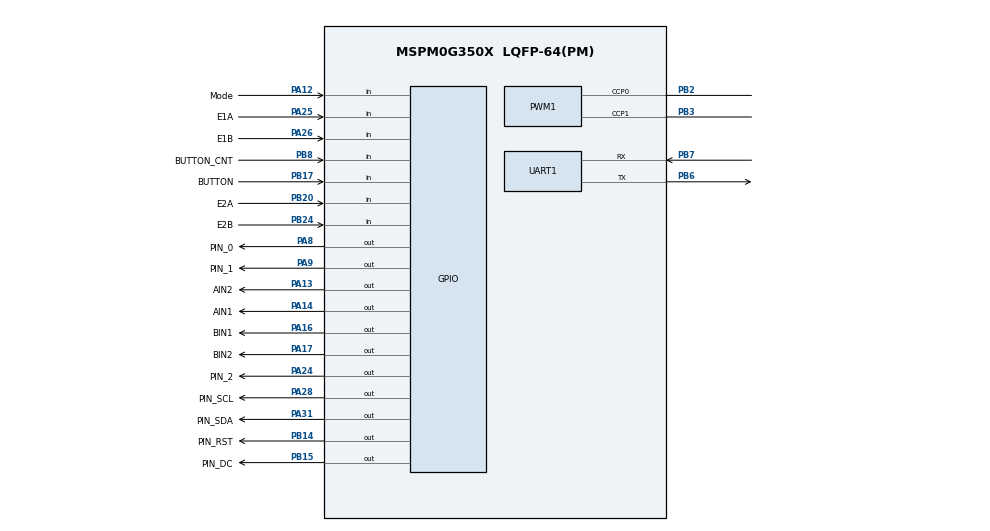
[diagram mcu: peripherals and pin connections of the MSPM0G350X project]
/**
 *
 * @cliArgs --device "MSPM0G350X" --part "Default" --package "LQFP-64(PM)" --product "mspm0_sdk@2.10.00.04"
 * @versions {"tool":"1.28.0+4696"}
 */

/**
 * Import the modules used in this configuration.
 */
const ADC12   = scripting.addModule("/ti/driverlib/ADC12", {}, false);
const ADC121  = ADC12.addInstance();
const DMA     = scripting.addModule("/ti/driverlib/DMA");
const GPIO    = scripting.addModule("/ti/driverlib/GPIO", {}, false);
const GPIO1   = GPIO.addInstance();
const GPIO2   = GPIO.addInstance();
const GPIO3   = GPIO.addInstance();
const GPIO4   = GPIO.addInstance();
const GPIO5   = GPIO.addInstance();
const GPIO6   = GPIO.addInstance();
const GPIO7   = GPIO.addInstance();
const GPIO8   = GPIO.addInstance();
const GPIO9   = GPIO.addInstance();
const GPIO10  = GPIO.addInstance();
const PWM     = scripting.addModule("/ti/driverlib/PWM", {}, false);
const PWM1    = PWM.addInstance();
const SYSCTL  = scripting.addModule("/ti/driverlib/SYSCTL");
const SYSTICK = scripting.addModule("/ti/driverlib/SYSTICK");
const TIMER   = scripting.addModule("/ti/driverlib/TIMER", {}, false);
const TIMER1  = TIMER.addInstance();
const UART    = scripting.addModule("/ti/driverlib/UART", {}, false);
const UART1   = UART.addInstance();

/**
 * Write custom configuration values to the imported modules.
 */
const divider7       = system.clockTree["PLL_PDIV"];
divider7.divideValue = 2;

const divider9       = system.clockTree["UDIV"];
divider9.divideValue = 2;

const multiplier2         = system.clockTree["PLL_QDIV"];
multiplier2.multiplyValue = 5;

const mux8       = system.clockTree["HSCLKMUX"];
mux8.inputSelect = "HSCLKMUX_SYSPLL2X";

ADC121.$name                      = "ADC12_0";
ADC121.sampleTime0                = "2 us";
ADC121.sampClkDiv                 = "DL_ADC12_CLOCK_DIVIDE_8";
ADC121.enabledInterrupts          = ["DL_ADC12_INTERRUPT_MEM0_RESULT_LOADED"];
ADC121.adcMem0_name               = "ADC_CH0";
ADC121.repeatMode                 = true;
ADC121.peripheral.$assign         = "ADC0";
ADC121.peripheral.adcPin0.$assign = "PA27";
ADC121.adcPin0Config.$name        = "ti_driverlib_gpio_GPIOPinGeneric2";

const Board = scripting.addModule("/ti/driverlib/Board", {}, false);

GPIO1.$name                         = "Gray_Address";
GPIO1.associatedPins.create(3);
GPIO1.associatedPins[0].$name       = "PIN_0";
GPIO1.associatedPins[0].pin.$assign = "PA8";
GPIO1.associatedPins[1].$name       = "PIN_1";
GPIO1.associatedPins[1].pin.$assign = "PA9";
GPIO1.associatedPins[2].$name       = "PIN_2";
GPIO1.associatedPins[2].pin.$assign = "PA24";

GPIO2.$name                         = "AIN";
GPIO2.port                          = "PORTA";
GPIO2.associatedPins.create(2);
GPIO2.associatedPins[0].$name       = "AIN1";
GPIO2.associatedPins[0].pin.$assign = "PA14";
GPIO2.associatedPins[1].$name       = "AIN2";
GPIO2.associatedPins[1].pin.$assign = "PA13";

GPIO3.$name                         = "BIN";
GPIO3.port                          = "PORTA";
GPIO3.associatedPins.create(2);
GPIO3.associatedPins[0].$name       = "BIN1";
GPIO3.associatedPins[0].pin.$assign = "PA16";
GPIO3.associatedPins[1].$name       = "BIN2";
GPIO3.associatedPins[1].pin.$assign = "PA17";

GPIO4.$name                               = "ENCODERA";
GPIO4.associatedPins.create(3);
GPIO4.associatedPins[0].$name             = "E1A";
GPIO4.associatedPins[0].direction         = "INPUT";
GPIO4.associatedPins[0].interruptEn       = true;
GPIO4.associatedPins[0].polarity          = "RISE";
GPIO4.associatedPins[0].interruptPriority = "0";
GPIO4.associatedPins[0].pin.$assign       = "PA25";
GPIO4.associatedPins[1].$name             = "E1B";
GPIO4.associatedPins[1].direction         = "INPUT";
GPIO4.associatedPins[1].interruptEn       = true;
GPIO4.associatedPins[1].polarity          = "RISE";
GPIO4.associatedPins[1].pin.$assign       = "PA26";
GPIO4.associatedPins[2].$name             = "Mode";
GPIO4.associatedPins[2].direction         = "INPUT";
GPIO4.associatedPins[2].interruptEn       = true;
GPIO4.associatedPins[2].polarity          = "FALL";
GPIO4.associatedPins[2].internalResistor  = "PULL_UP";
GPIO4.associatedPins[2].pin.$assign       = "PA12";

GPIO5.$name                               = "ENCODERB";
GPIO5.associatedPins.create(3);
GPIO5.associatedPins[0].$name             = "E2A";
GPIO5.associatedPins[0].direction         = "INPUT";
GPIO5.associatedPins[0].interruptEn       = true;
GPIO5.associatedPins[0].polarity          = "RISE";
GPIO5.associatedPins[0].interruptPriority = "0";
GPIO5.associatedPins[0].pin.$assign       = "PB20";
GPIO5.associatedPins[1].$name             = "E2B";
GPIO5.associatedPins[1].direction         = "INPUT";
GPIO5.associatedPins[1].polarity          = "RISE_FALL";
GPIO5.associatedPins[1].interruptEn       = true;
GPIO5.associatedPins[1].pin.$assign       = "PB24";
GPIO5.associatedPins[2].$name             = "BUTTON";
GPIO5.associatedPins[2].direction         = "INPUT";
GPIO5.associatedPins[2].internalResistor  = "PULL_UP";
GPIO5.associatedPins[2].interruptEn       = true;
GPIO5.associatedPins[2].polarity          = "FALL";
GPIO5.associatedPins[2].pin.$assign       = "PB17";

GPIO6.$name                         = "OLED_RST";
GPIO6.associatedPins[0].$name       = "PIN_RST";
GPIO6.associatedPins[0].pin.$assign = "PB14";

GPIO7.$name                         = "OLED_DC";
GPIO7.associatedPins[0].$name       = "PIN_DC";
GPIO7.associatedPins[0].pin.$assign = "PB15";

GPIO8.$name                         = "OLED_SCL";
GPIO8.associatedPins[0].$name       = "PIN_SCL";
GPIO8.associatedPins[0].pin.$assign = "PA28";

GPIO9.$name                         = "OLED_SDA";
GPIO9.associatedPins[0].$name       = "PIN_SDA";
GPIO9.associatedPins[0].pin.$assign = "PA31";

GPIO10.$name                              = "COUNT_BTN";
GPIO10.associatedPins[0].$name            = "BUTTON_CNT";
GPIO10.associatedPins[0].direction        = "INPUT";
GPIO10.associatedPins[0].internalResistor = "PULL_UP";
GPIO10.associatedPins[0].polarity         = "FALL";
GPIO10.associatedPins[0].pin.$assign      = "PB8";

PWM1.$name                      = "PWM_0";
PWM1.pwmMode                    = "EDGE_ALIGN_UP";
PWM1.timerStartTimer            = true;
PWM1.timerCount                 = 8000;
PWM1.peripheral.$assign         = "TIMA1";
PWM1.peripheral.ccp0Pin.$assign = "PB2";
PWM1.peripheral.ccp1Pin.$assign = "PB3";
PWM1.PWM_CHANNEL_0.$name        = "ti_driverlib_pwm_PWMTimerCC0";
PWM1.PWM_CHANNEL_1.$name        = "ti_driverlib_pwm_PWMTimerCC1";
PWM1.ccp0PinConfig.$name        = "ti_driverlib_gpio_GPIOPinGeneric3";
PWM1.ccp1PinConfig.$name        = "ti_driverlib_gpio_GPIOPinGeneric4";

SYSCTL.forceDefaultClkConfig = true;
SYSCTL.clockTreeEn           = true;

SYSTICK.periodEnable    = true;
SYSTICK.period          = 32000;
SYSTICK.interruptEnable = true;
SYSTICK.systickEnable   = true;

TIMER1.$name             = "TIMER_0";
TIMER1.timerPeriod       = "10 ms";
TIMER1.timerClkPrescale  = 32;
TIMER1.timerMode         = "PERIODIC_UP";
TIMER1.interrupts        = ["ZERO"];
TIMER1.interruptPriority = "1";

UART1.enabledInterrupts                    = ["RX"];
UART1.$name                                = "UART_JY61P";
UART1.interruptPriority                    = "0";
UART1.enabledDMARXTriggers                 = "DL_UART_DMA_INTERRUPT_RX";
UART1.targetBaudRate                       = 115200;
UART1.peripheral.$assign                   = "UART1";
UART1.peripheral.rxPin.$assign             = "PB7";
UART1.peripheral.txPin.$assign             = "PB6";
UART1.txPinConfig.direction                = scripting.forceWrite("OUTPUT");
UART1.txPinConfig.hideOutputInversion      = scripting.forceWrite(false);
UART1.txPinConfig.onlyInternalResistor     = scripting.forceWrite(false);
UART1.txPinConfig.passedPeripheralType     = scripting.forceWrite("Digital");
UART1.txPinConfig.$name                    = "ti_driverlib_gpio_GPIOPinGeneric0";
UART1.rxPinConfig.hideOutputInversion      = scripting.forceWrite(false);
UART1.rxPinConfig.onlyInternalResistor     = scripting.forceWrite(false);
UART1.rxPinConfig.passedPeripheralType     = scripting.forceWrite("Digital");
UART1.rxPinConfig.$name                    = "ti_driverlib_gpio_GPIOPinGeneric1";
UART1.DMA_CHANNEL_RX.configureTransferSize = true;
UART1.DMA_CHANNEL_RX.transferSize          = 66;
UART1.DMA_CHANNEL_RX.srcLength             = "BYTE";
UART1.DMA_CHANNEL_RX.dstLength             = "BYTE";
UART1.DMA_CHANNEL_RX.$name                 = "DMA_UART_JY61P";
UART1.DMA_CHANNEL_RX.transferMode          = "FULL_CH_REPEAT_SINGLE";
UART1.DMA_CHANNEL_RX.addressMode           = "f2b";

/**
 * Pinmux solution for unlocked pins/peripherals. This ensures that minor changes to the automatic solver in a future
 * version of the tool will not impact the pinmux you originally saw.  These lines can be completely deleted in order to
 * re-solve from scratch.
 */
Board.peripheral.$suggestSolution                = "DEBUGSS";
Board.peripheral.swclkPin.$suggestSolution       = "PA20";
Board.peripheral.swdioPin.$suggestSolution       = "PA19";
TIMER1.peripheral.$suggestSolution               = "TIMA0";
UART1.DMA_CHANNEL_RX.peripheral.$suggestSolution = "DMA_CH0";
